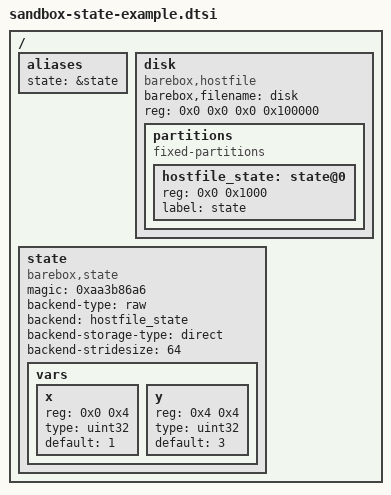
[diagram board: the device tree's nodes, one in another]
/ {
	aliases {
		state = &state;
	};

	disk {
		compatible = "barebox,hostfile";
		barebox,filename = "disk";
		reg = <0x0 0x0 0x0 0x100000>;

		partitions {
			compatible = "fixed-partitions";
			#address-cells = <1>;
			#size-cells = <1>;

			hostfile_state: state@0 {
				reg = <0x0 0x1000>;
				label = "state";
			};
		};
	};

	state: state {
		magic = <0xaa3b86a6>;
		compatible = "barebox,state";
		backend-type = "raw";
		backend = <&hostfile_state>;
		backend-storage-type = "direct";
		backend-stridesize = <64>;

		#address-cells = <1>;
		#size-cells = <1>;
		vars {
			#address-cells = <1>;
			#size-cells = <1>;

			x {
				reg = <0x0 0x4>;
				type = "uint32";
				default = <1>;
			};

			y {
				reg = <0x4 0x4>;
				type = "uint32";
				default = <3>;
			};
		};
	};
};
